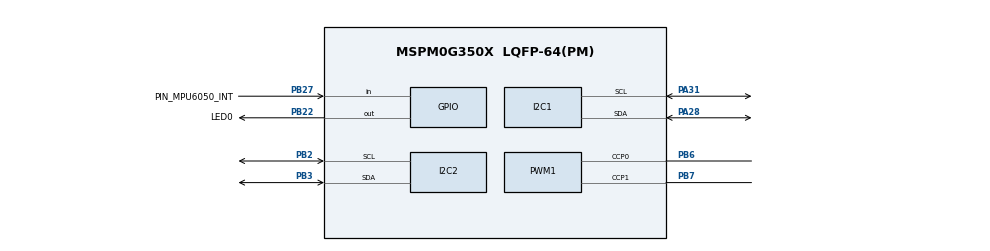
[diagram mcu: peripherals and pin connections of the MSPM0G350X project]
/**
 * @cliArgs --device "MSPM0G350X" --part "Default" --package "LQFP-64(PM)" --product "mspm0_sdk@2.10.00.04"
 * @versions {"tool":"1.27.0+4565"}
 */

/**
 * Import the modules used in this configuration.
 */
const GPIO   = scripting.addModule("/ti/driverlib/GPIO", {}, false);
const GPIO1  = GPIO.addInstance();
const GPIO2  = GPIO.addInstance();
const GPIO3  = GPIO.addInstance();
const GPIO4  = GPIO.addInstance();
const GPIO5  = GPIO.addInstance();
const GPIO6  = GPIO.addInstance();
const GPIO7  = GPIO.addInstance();
const I2C    = scripting.addModule("/ti/driverlib/I2C", {}, false);
const I2C1   = I2C.addInstance();
const I2C2   = I2C.addInstance();
const PWM    = scripting.addModule("/ti/driverlib/PWM", {}, false);
const PWM1   = PWM.addInstance();
const SYSCTL = scripting.addModule("/ti/driverlib/SYSCTL");
const TIMER  = scripting.addModule("/ti/driverlib/TIMER", {}, false);
const TIMER1 = TIMER.addInstance();
const TIMER2 = TIMER.addInstance();

/**
 * Write custom configuration values to the imported modules.
 */
const divider7       = system.clockTree["PLL_PDIV"];
divider7.divideValue = 2;

const divider9       = system.clockTree["UDIV"];
divider9.divideValue = 2;

const multiplier2         = system.clockTree["PLL_QDIV"];
multiplier2.multiplyValue = 5;

const mux8       = system.clockTree["HSCLKMUX"];
mux8.inputSelect = "HSCLKMUX_SYSPLL2X";

GPIO1.$name                               = "GPIO_MPU6050";
GPIO1.associatedPins[0].direction         = "INPUT";
GPIO1.associatedPins[0].internalResistor  = "PULL_UP";
GPIO1.associatedPins[0].interruptEn       = true;
GPIO1.associatedPins[0].polarity          = "FALL";
GPIO1.associatedPins[0].$name             = "PIN_MPU6050_INT";
GPIO1.associatedPins[0].interruptPriority = "1";
GPIO1.associatedPins[0].pin.$assign       = "PB27";

const Board = scripting.addModule("/ti/driverlib/Board", {}, false);

GPIO2.$name                          = "LED";
GPIO2.associatedPins[0].$name        = "LED0";
GPIO2.associatedPins[0].assignedPort = "PORTB";
GPIO2.associatedPins[0].assignedPin  = "22";
GPIO2.associatedPins[0].pin.$assign  = "PB22";

GPIO3.$name                               = "KEY";
GPIO3.port                                = "PORTB";
GPIO3.associatedPins.create(5);
GPIO3.associatedPins[0].$name             = "PIN_21";
GPIO3.associatedPins[0].internalResistor  = "PULL_UP";
GPIO3.associatedPins[0].assignedPin       = "21";
GPIO3.associatedPins[0].direction         = "INPUT";
GPIO3.associatedPins[0].interruptEn       = true;
GPIO3.associatedPins[0].polarity          = "RISE";
GPIO3.associatedPins[0].interruptPriority = "1";
GPIO3.associatedPins[1].$name             = "T1";
GPIO3.associatedPins[1].direction         = "INPUT";
GPIO3.associatedPins[1].internalResistor  = "PULL_UP";
GPIO3.associatedPins[1].interruptEn       = true;
GPIO3.associatedPins[1].interruptPriority = "1";
GPIO3.associatedPins[1].assignedPin       = "10";
GPIO3.associatedPins[1].polarity          = "FALL";
GPIO3.associatedPins[2].$name             = "T2";
GPIO3.associatedPins[2].internalResistor  = "PULL_UP";
GPIO3.associatedPins[2].direction         = "INPUT";
GPIO3.associatedPins[2].assignedPin       = "11";
GPIO3.associatedPins[2].interruptEn       = true;
GPIO3.associatedPins[2].interruptPriority = "1";
GPIO3.associatedPins[2].polarity          = "FALL";
GPIO3.associatedPins[3].$name             = "T3";
GPIO3.associatedPins[3].direction         = "INPUT";
GPIO3.associatedPins[3].interruptEn       = true;
GPIO3.associatedPins[3].interruptPriority = "1";
GPIO3.associatedPins[3].polarity          = "FALL";
GPIO3.associatedPins[3].internalResistor  = "PULL_UP";
GPIO3.associatedPins[3].assignedPin       = "14";
GPIO3.associatedPins[4].$name             = "T4";
GPIO3.associatedPins[4].direction         = "INPUT";
GPIO3.associatedPins[4].assignedPin       = "19";
GPIO3.associatedPins[4].interruptEn       = true;
GPIO3.associatedPins[4].polarity          = "FALL";
GPIO3.associatedPins[4].interruptPriority = "1";
GPIO3.associatedPins[4].internalResistor  = "PULL_UP";

GPIO4.$name                          = "MOTOR";
GPIO4.port                           = "PORTA";
GPIO4.associatedPins.create(5);
GPIO4.associatedPins[0].$name        = "AIN1";
GPIO4.associatedPins[0].assignedPin  = "8";
GPIO4.associatedPins[1].$name        = "AIN2";
GPIO4.associatedPins[1].assignedPin  = "9";
GPIO4.associatedPins[2].$name        = "BIN1";
GPIO4.associatedPins[2].assignedPin  = "0";
GPIO4.associatedPins[3].$name        = "BIN2";
GPIO4.associatedPins[3].assignedPin  = "1";
GPIO4.associatedPins[4].$name        = "STBY";
GPIO4.associatedPins[4].assignedPin  = "11";
GPIO4.associatedPins[4].initialValue = "SET";

GPIO5.$name                               = "ENCODER";
GPIO5.associatedPins.create(4);
GPIO5.associatedPins[0].$name             = "E1A";
GPIO5.associatedPins[0].direction         = "INPUT";
GPIO5.associatedPins[0].assignedPort      = "PORTA";
GPIO5.associatedPins[0].assignedPin       = "16";
GPIO5.associatedPins[0].internalResistor  = "PULL_DOWN";
GPIO5.associatedPins[0].interruptEn       = true;
GPIO5.associatedPins[0].polarity          = "RISE";
GPIO5.associatedPins[0].interruptPriority = "1";
GPIO5.associatedPins[1].$name             = "E1B";
GPIO5.associatedPins[1].direction         = "INPUT";
GPIO5.associatedPins[1].internalResistor  = "PULL_DOWN";
GPIO5.associatedPins[1].assignedPort      = "PORTA";
GPIO5.associatedPins[1].assignedPin       = "17";
GPIO5.associatedPins[2].$name             = "E2A";
GPIO5.associatedPins[2].direction         = "INPUT";
GPIO5.associatedPins[2].assignedPort      = "PORTB";
GPIO5.associatedPins[2].assignedPin       = "0";
GPIO5.associatedPins[2].internalResistor  = "PULL_DOWN";
GPIO5.associatedPins[2].interruptEn       = true;
GPIO5.associatedPins[2].polarity          = "RISE";
GPIO5.associatedPins[2].interruptPriority = "1";
GPIO5.associatedPins[3].$name             = "E2B";
GPIO5.associatedPins[3].direction         = "INPUT";
GPIO5.associatedPins[3].polarity          = "RISE";
GPIO5.associatedPins[3].assignedPort      = "PORTB";
GPIO5.associatedPins[3].assignedPin       = "1";
GPIO5.associatedPins[3].internalResistor  = "PULL_DOWN";

GPIO6.$name                          = "GRAY";
GPIO6.port                           = "PORTA";
GPIO6.associatedPins.create(8);
GPIO6.associatedPins[0].$name        = "S1";
GPIO6.associatedPins[0].direction    = "INPUT";
GPIO6.associatedPins[0].assignedPin  = "14";
GPIO6.associatedPins[1].$name        = "S2";
GPIO6.associatedPins[1].direction    = "INPUT";
GPIO6.associatedPins[1].assignedPin  = "15";
GPIO6.associatedPins[2].$name        = "S3";
GPIO6.associatedPins[2].direction    = "INPUT";
GPIO6.associatedPins[2].assignedPin  = "21";
GPIO6.associatedPins[3].$name        = "S4";
GPIO6.associatedPins[3].direction    = "INPUT";
GPIO6.associatedPins[3].assignedPin  = "22";
GPIO6.associatedPins[4].$name        = "S5";
GPIO6.associatedPins[4].assignedPin  = "24";
GPIO6.associatedPins[4].initialValue = "SET";
GPIO6.associatedPins[4].direction    = "INPUT";
GPIO6.associatedPins[5].$name        = "S6";
GPIO6.associatedPins[5].assignedPin  = "25";
GPIO6.associatedPins[5].direction    = "INPUT";
GPIO6.associatedPins[6].$name        = "S7";
GPIO6.associatedPins[6].assignedPin  = "26";
GPIO6.associatedPins[6].direction    = "INPUT";
GPIO6.associatedPins[7].$name        = "S8";
GPIO6.associatedPins[7].direction    = "INPUT";
GPIO6.associatedPins[7].assignedPin  = "27";

GPIO7.$name                         = "ALARM";
GPIO7.port                          = "PORTB";
GPIO7.associatedPins.create(2);
GPIO7.associatedPins[0].$name       = "BUZZER";
GPIO7.associatedPins[0].assignedPin = "17";
GPIO7.associatedPins[1].$name       = "ALED";
GPIO7.associatedPins[1].assignedPin = "18";

I2C1.$name                             = "I2C_MPU6050";
I2C1.basicEnableController             = true;
I2C1.basicControllerStandardBusSpeed   = "Fast";
I2C1.peripheral.$assign                = "I2C0";
I2C1.peripheral.sdaPin.$assign         = "PA28";
I2C1.peripheral.sclPin.$assign         = "PA31";
I2C1.sdaPinConfig.$name                = "ti_driverlib_gpio_GPIOPinGeneric0";
I2C1.sdaPinConfig.hideOutputInversion  = scripting.forceWrite(false);
I2C1.sdaPinConfig.onlyInternalResistor = scripting.forceWrite(false);
I2C1.sdaPinConfig.passedPeripheralType = scripting.forceWrite("Digital");
I2C1.sclPinConfig.$name                = "ti_driverlib_gpio_GPIOPinGeneric1";
I2C1.sclPinConfig.hideOutputInversion  = scripting.forceWrite(false);
I2C1.sclPinConfig.onlyInternalResistor = scripting.forceWrite(false);
I2C1.sclPinConfig.passedPeripheralType = scripting.forceWrite("Digital");

I2C2.$name                             = "I2C_OLED";
I2C2.basicEnableController             = true;
I2C2.basicControllerStandardBusSpeed   = "Fast";
I2C2.peripheral.$assign                = "I2C1";
I2C2.peripheral.sdaPin.$assign         = "PB3";
I2C2.peripheral.sclPin.$assign         = "PB2";
I2C2.sdaPinConfig.hideOutputInversion  = scripting.forceWrite(false);
I2C2.sdaPinConfig.onlyInternalResistor = scripting.forceWrite(false);
I2C2.sdaPinConfig.passedPeripheralType = scripting.forceWrite("Digital");
I2C2.sdaPinConfig.$name                = "ti_driverlib_gpio_GPIOPinGeneric6";
I2C2.sdaPinConfig.enableConfig         = true;
I2C2.sdaPinConfig.internalResistor     = "PULL_UP";
I2C2.sclPinConfig.hideOutputInversion  = scripting.forceWrite(false);
I2C2.sclPinConfig.onlyInternalResistor = scripting.forceWrite(false);
I2C2.sclPinConfig.passedPeripheralType = scripting.forceWrite("Digital");
I2C2.sclPinConfig.$name                = "ti_driverlib_gpio_GPIOPinGeneric7";
I2C2.sclPinConfig.enableConfig         = true;
I2C2.sclPinConfig.internalResistor     = "PULL_UP";

PWM1.$name                      = "PWM_0";
PWM1.timerCount                 = 1600;
PWM1.pwmMode                    = "EDGE_ALIGN_UP";
PWM1.clockDivider               = 5;
PWM1.timerStartTimer            = true;
PWM1.peripheral.$assign         = "TIMG6";
PWM1.peripheral.ccp0Pin.$assign = "PB6";
PWM1.peripheral.ccp1Pin.$assign = "PB7";
PWM1.PWM_CHANNEL_0.$name        = "ti_driverlib_pwm_PWMTimerCC0";
PWM1.PWM_CHANNEL_1.$name        = "ti_driverlib_pwm_PWMTimerCC1";
PWM1.ccp0PinConfig.$name        = "ti_driverlib_gpio_GPIOPinGeneric2";
PWM1.ccp1PinConfig.$name        = "ti_driverlib_gpio_GPIOPinGeneric3";

SYSCTL.forceDefaultClkConfig = true;
SYSCTL.clockTreeEn           = true;

TIMER1.$name              = "Timer_Speed";
TIMER1.timerClkPrescale   = 256;
TIMER1.timerMode          = "PERIODIC_UP";
TIMER1.interrupts         = ["ZERO"];
TIMER1.interruptPriority  = "1";
TIMER1.timerPeriod        = "20ms";
TIMER1.peripheral.$assign = "TIMG7";

TIMER2.$name              = "Timer_10ms";
TIMER2.timerPeriod        = "10ms";
TIMER2.timerClkPrescale   = 256;
TIMER2.timerMode          = "PERIODIC_UP";
TIMER2.interrupts         = ["ZERO"];
TIMER2.interruptPriority  = "1";
TIMER2.peripheral.$assign = "TIMG0";

/**
 * Pinmux solution for unlocked pins/peripherals. This ensures that minor changes to the automatic solver in a future
 * version of the tool will not impact the pinmux you originally saw.  These lines can be completely deleted in order to
 * re-solve from scratch.
 */
Board.peripheral.$suggestSolution            = "DEBUGSS";
Board.peripheral.swclkPin.$suggestSolution   = "PA20";
Board.peripheral.swdioPin.$suggestSolution   = "PA19";
GPIO3.associatedPins[0].pin.$suggestSolution = "PB21";
GPIO3.associatedPins[1].pin.$suggestSolution = "PB10";
GPIO3.associatedPins[2].pin.$suggestSolution = "PB11";
GPIO3.associatedPins[3].pin.$suggestSolution = "PB14";
GPIO3.associatedPins[4].pin.$suggestSolution = "PB19";
GPIO4.associatedPins[0].pin.$suggestSolution = "PA8";
GPIO4.associatedPins[1].pin.$suggestSolution = "PA9";
GPIO4.associatedPins[2].pin.$suggestSolution = "PA0";
GPIO4.associatedPins[3].pin.$suggestSolution = "PA1";
GPIO4.associatedPins[4].pin.$suggestSolution = "PA11";
GPIO5.associatedPins[0].pin.$suggestSolution = "PA16";
GPIO5.associatedPins[1].pin.$suggestSolution = "PA17";
GPIO5.associatedPins[2].pin.$suggestSolution = "PB0";
GPIO5.associatedPins[3].pin.$suggestSolution = "PB1";
GPIO6.associatedPins[0].pin.$suggestSolution = "PA14";
GPIO6.associatedPins[1].pin.$suggestSolution = "PA15";
GPIO6.associatedPins[2].pin.$suggestSolution = "PA21";
GPIO6.associatedPins[3].pin.$suggestSolution = "PA22";
GPIO6.associatedPins[4].pin.$suggestSolution = "PA24";
GPIO6.associatedPins[5].pin.$suggestSolution = "PA25";
GPIO6.associatedPins[6].pin.$suggestSolution = "PA26";
GPIO6.associatedPins[7].pin.$suggestSolution = "PA27";
GPIO7.associatedPins[0].pin.$suggestSolution = "PB17";
GPIO7.associatedPins[1].pin.$suggestSolution = "PB18";
